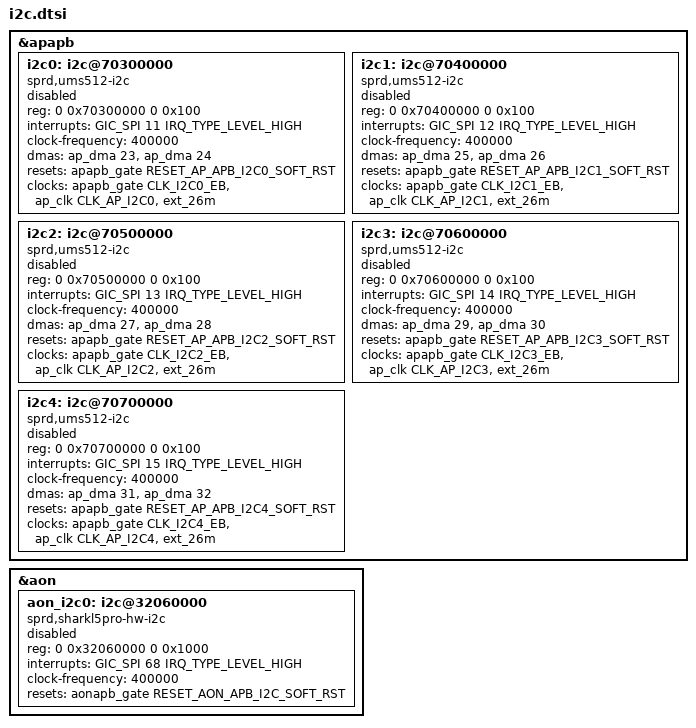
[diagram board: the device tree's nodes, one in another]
// SPDX-License-Identifier: (GPL-2.0+ OR MIT)
/*
 * Unisoc I2C dts file
 *
 * Copyright (C) 2020, Unisoc Inc.
 *
 */

&apapb {
	i2c0: i2c@70300000 {
		compatible = "sprd,ums512-i2c", "sprd,sc9860-i2c";
		reg = <0 0x70300000 0 0x100>;
		interrupts = <GIC_SPI 11 IRQ_TYPE_LEVEL_HIGH>;
		clock-frequency = <400000>;
		#address-cells = <1>;
		#size-cells = <0>;
		dma-names = "rx", "tx";
		dmas = <&ap_dma 23 &ap_dma 24>;
		status = "disabled";
		reset-names = "i2c_rst";
		resets = <&apapb_gate RESET_AP_APB_I2C0_SOFT_RST>;
	};

	i2c1: i2c@70400000 {
		compatible = "sprd,ums512-i2c", "sprd,sc9860-i2c";
		reg = <0 0x70400000 0 0x100>;
		interrupts = <GIC_SPI 12 IRQ_TYPE_LEVEL_HIGH>;
		clock-frequency = <400000>;
		#address-cells = <1>;
		#size-cells = <0>;
		dma-names = "rx", "tx";
		dmas = <&ap_dma 25 &ap_dma 26>;
		status = "disabled";
		reset-names = "i2c_rst";
		resets = <&apapb_gate RESET_AP_APB_I2C1_SOFT_RST>;
	};

	i2c2: i2c@70500000 {
		compatible = "sprd,ums512-i2c", "sprd,sc9860-i2c";
		reg = <0 0x70500000 0 0x100>;
		interrupts = <GIC_SPI 13 IRQ_TYPE_LEVEL_HIGH>;
		clock-frequency = <400000>;
		#address-cells = <1>;
		#size-cells = <0>;
		dma-names = "rx", "tx";
		dmas = <&ap_dma 27 &ap_dma 28>;
		status = "disabled";
		reset-names = "i2c_rst";
		resets = <&apapb_gate RESET_AP_APB_I2C2_SOFT_RST>;
	};

	i2c3: i2c@70600000 {
		compatible = "sprd,ums512-i2c", "sprd,sc9860-i2c";
		reg = <0 0x70600000 0 0x100>;
		interrupts = <GIC_SPI 14 IRQ_TYPE_LEVEL_HIGH>;
		clock-frequency = <400000>;
		#address-cells = <1>;
		#size-cells = <0>;
		dma-names = "rx", "tx";
		dmas = <&ap_dma 29 &ap_dma 30>;
		status = "disabled";
		reset-names = "i2c_rst";
		resets = <&apapb_gate RESET_AP_APB_I2C3_SOFT_RST>;
	};

	i2c4: i2c@70700000 {
		compatible = "sprd,ums512-i2c", "sprd,sc9860-i2c";
		reg = <0 0x70700000 0 0x100>;
		interrupts = <GIC_SPI 15 IRQ_TYPE_LEVEL_HIGH>;
		clock-frequency = <400000>;
		#address-cells = <1>;
		#size-cells = <0>;
		dma-names = "rx", "tx";
		dmas = <&ap_dma 31 &ap_dma 32>;
		status = "disabled";
		reset-names = "i2c_rst";
		resets = <&apapb_gate RESET_AP_APB_I2C4_SOFT_RST>;
	};

};

&i2c0 {
	clock-names = "enable", "i2c", "source";
        clocks = <&apapb_gate CLK_I2C0_EB>,
		 <&ap_clk CLK_AP_I2C0>, <&ext_26m>;
};

&i2c1 {
	clock-names = "enable", "i2c", "source";
        clocks = <&apapb_gate CLK_I2C1_EB>,
		 <&ap_clk CLK_AP_I2C1>, <&ext_26m>;
};

&i2c2 {
	clock-names = "enable", "i2c", "source";
        clocks = <&apapb_gate CLK_I2C2_EB>,
		 <&ap_clk CLK_AP_I2C2>, <&ext_26m>;
};

&i2c3 {
	clock-names = "enable", "i2c", "source";
        clocks = <&apapb_gate CLK_I2C3_EB>,
		 <&ap_clk CLK_AP_I2C3>, <&ext_26m>;
};

&i2c4 {
	clock-names = "enable", "i2c", "source";
        clocks = <&apapb_gate CLK_I2C4_EB>,
		 <&ap_clk CLK_AP_I2C4>, <&ext_26m>;
};

&aon {
	aon_i2c0: i2c@32060000 {
		compatible = "sprd,sharkl5pro-hw-i2c";
		reg = <0 0x32060000 0 0x1000>;
		interrupts = <GIC_SPI 68 IRQ_TYPE_LEVEL_HIGH>;
		clock-names = "source", "enable", "i2c",
				"clk_hw_i2c";
		clock-frequency = <400000>;
		#address-cells = <1>;
		#size-cells = <0>;
		status = "disabled";
		reset-names = "i2c_rst";
		resets = <&aonapb_gate RESET_AON_APB_I2C_SOFT_RST>;
	};

};



